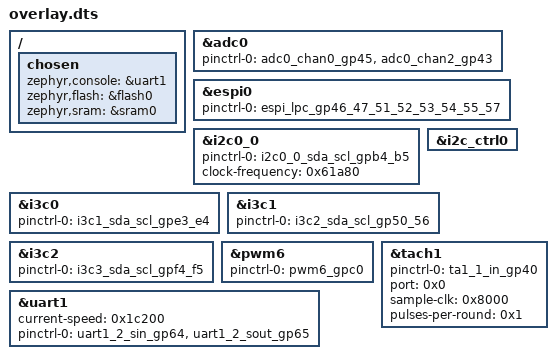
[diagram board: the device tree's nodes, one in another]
/ {
	chosen {
		zephyr,console = &uart1;
		zephyr,flash = &flash0;
		zephyr,sram = &sram0;
	};
};
&adc0{
	status = "okay";
	pinctrl-0 = < &adc0_chan0_gp45 &adc0_chan2_gp43 >;
	pinctrl-names = "default";
};
&espi0{
	status = "okay";
	pinctrl-0 = < &espi_lpc_gp46_47_51_52_53_54_55_57 >;
	pinctrl-names = "default";
};
&i2c0_0{
	status = "okay";
	pinctrl-0 = < &i2c0_0_sda_scl_gpb4_b5 >;
	pinctrl-names = "default";
	clock-frequency = < 0x61a80 >;
};
&i2c_ctrl0{
	status = "okay";
};
&i3c0{
	pinctrl-0 = < &i3c1_sda_scl_gpe3_e4 >;
	pinctrl-names = "default";
};
&i3c1{
	pinctrl-0 = < &i3c2_sda_scl_gp50_56 >;
	pinctrl-names = "default";
};
&i3c2{
	pinctrl-0 = < &i3c3_sda_scl_gpf4_f5 >;
	pinctrl-names = "default";
};
&pwm6{
	status = "okay";
	pinctrl-0 = < &pwm6_gpc0 >;
	pinctrl-names = "default";
};
&tach1{
	status = "okay";
	pinctrl-0 = < &ta1_1_in_gp40 >;
	pinctrl-names = "default";
	port = < 0x0 >;
	sample-clk = < 0x8000 >;
	pulses-per-round = < 0x1 >;
};
&uart1{
	status = "okay";
	current-speed = < 0x1c200 >;
	pinctrl-0 = < &uart1_2_sin_gp64 &uart1_2_sout_gp65 >;
	pinctrl-names = "default";
};
